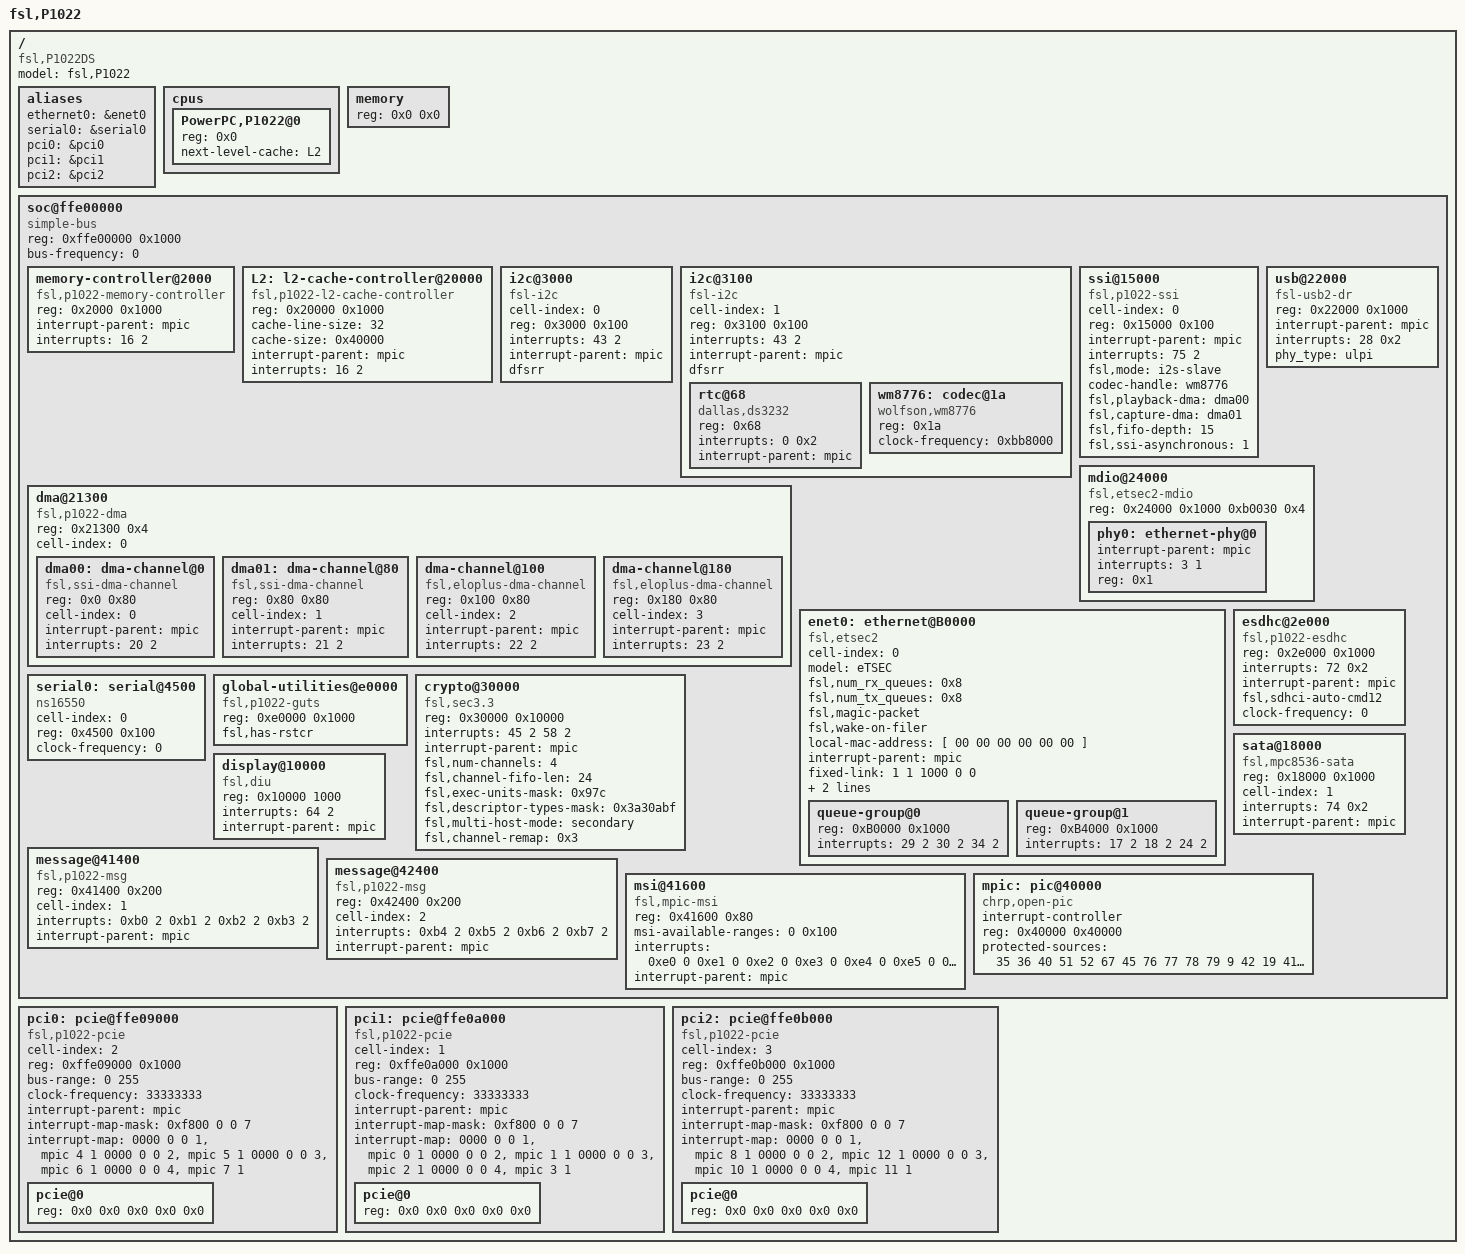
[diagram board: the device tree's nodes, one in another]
/*
 * P1022 DS Core0 Device Tree Source in CAMP mode.
 *
 * In CAMP mode, each core needs to have its own dts. Only mpic and L2 cache
 * can be shared, all the other devices must be assigned to one core only.
 * This dts file allows core0 to have memory, l2, i2c, dma1, global-util, eth0,
 * usb, esdhc, crypto, pcie0, pcie2, sata1.
 *
 * Copyright 2010-2011 Freescale Semiconductor Inc.
 *
 * This program is free software; you can redistribute it and/or modify it
 * under the terms of the GNU General Public License as published by the
 * Free Software Foundation; either version 2 of the License, or (at your
 * option) any later version.
 */

/dts-v1/;
/ {
	model = "fsl,P1022";
	compatible = "fsl,P1022DS", "fsl,P1022DS-CAMP";
	#address-cells = <1>;
	#size-cells = <1>;

	aliases {
		ethernet0 = &enet0;
		serial0 = &serial0;
		pci0 = &pci0;
		pci1 = &pci1;
		pci2 = &pci2;
	};

	cpus {
		#address-cells = <1>;
		#size-cells = <0>;

		PowerPC,P1022@0 {
			device_type = "cpu";
			reg = <0x0>;
			next-level-cache = <&L2>;
		};

	};

	memory {
		device_type = "memory";
		reg = <0x0 0x0>;		// Filled by U-Boot
	};

	soc@ffe00000 {
		#address-cells = <1>;
		#size-cells = <1>;
		device_type = "soc";
		compatible = "simple-bus";
		ranges = <0x0 0xffe00000 0x100000>;
		// CCSRBAR & soc regs, remove once parse code for immrbase fixed
		reg = <0xffe00000 0x1000>;
		bus-frequency = <0>;		// Filled out by uboot.

		memory-controller@2000 {
			compatible = "fsl,p1022-memory-controller";
			reg = <0x2000 0x1000>;
			interrupt-parent = <&mpic>;
			interrupts = <16 2>;
		};

		L2: l2-cache-controller@20000 {
			compatible = "fsl,p1022-l2-cache-controller";
			reg = <0x20000 0x1000>;
			cache-line-size = <32>;	// 32 bytes
			cache-size = <0x40000>;	// L2, 256K
			interrupt-parent = <&mpic>;
			interrupts = <16 2>;
		};

		i2c@3000 {
			#address-cells = <1>;
			#size-cells = <0>;
			cell-index = <0>;
			compatible = "fsl-i2c";
			reg = <0x3000 0x100>;
			interrupts = <43 2>;
			interrupt-parent = <&mpic>;
			dfsrr;
		};

		i2c@3100 {
			#address-cells = <1>;
			#size-cells = <0>;
			cell-index = <1>;
			compatible = "fsl-i2c";
			reg = <0x3100 0x100>;
			interrupts = <43 2>;
			interrupt-parent = <&mpic>;
			dfsrr;
			rtc@68 {
				compatible = "dallas,ds3232";
				reg = <0x68>;
				interrupts = <0 0x2>;
				interrupt-parent = <&mpic>;
			};
			wm8776:codec@1a {
				compatible = "wolfson,wm8776";
				reg = <0x1a>;
				clock-frequency = <0xbb8000>;
			};
		};

		ssi@15000 {
			compatible = "fsl,p1022-ssi";
			cell-index = <0>;
			reg = <0x15000 0x100>;
			interrupt-parent = <&mpic>;
			interrupts = <75 2>;
			fsl,mode = "i2s-slave";
			codec-handle = <&wm8776>;
			fsl,playback-dma = <&dma00>;
			fsl,capture-dma = <&dma01>;
			fsl,fifo-depth = <15>;
			fsl,ssi-asynchronous = <1>;
		};

		dma@21300 {
			#address-cells = <1>;
			#size-cells = <1>;
			compatible = "fsl,p1022-dma", "fsl,eloplus-dma";
			reg = <0x21300 0x4>;
			ranges = <0x0 0x21100 0x200>;
			cell-index = <0>;
			dma00: dma-channel@0 {
				compatible = "fsl,ssi-dma-channel";
				reg = <0x0 0x80>;
				cell-index = <0>;
				interrupt-parent = <&mpic>;
				interrupts = <20 2>;
			};
			dma01: dma-channel@80 {
				compatible = "fsl,ssi-dma-channel";
				reg = <0x80 0x80>;
				cell-index = <1>;
				interrupt-parent = <&mpic>;
				interrupts = <21 2>;
			};
			dma-channel@100 {
				compatible = "fsl,eloplus-dma-channel";
				reg = <0x100 0x80>;
				cell-index = <2>;
				interrupt-parent = <&mpic>;
				interrupts = <22 2>;
			};
			dma-channel@180 {
				compatible = "fsl,eloplus-dma-channel";
				reg = <0x180 0x80>;
				cell-index = <3>;
				interrupt-parent = <&mpic>;
				interrupts = <23 2>;
			};
		};

		usb@22000 {
			#address-cells = <1>;
			#size-cells = <0>;
			compatible = "fsl-usb2-dr";
			reg = <0x22000 0x1000>;
			interrupt-parent = <&mpic>;
			interrupts = <28 0x2>;
			phy_type = "ulpi";
		};

		mdio@24000 {
			#address-cells = <1>;
			#size-cells = <0>;
			compatible = "fsl,etsec2-mdio";
			reg = <0x24000 0x1000 0xb0030 0x4>;

			phy0: ethernet-phy@0 {
				interrupt-parent = <&mpic>;
				interrupts = <3 1>;
				reg = <0x1>;
			};
		};

		enet0: ethernet@B0000 {
			#address-cells = <1>;
			#size-cells = <1>;
			cell-index = <0>;
			device_type = "network";
			model = "eTSEC";
			compatible = "fsl,etsec2";
			fsl,num_rx_queues = <0x8>;
			fsl,num_tx_queues = <0x8>;
			fsl,magic-packet;
			fsl,wake-on-filer;
			local-mac-address = [ 00 00 00 00 00 00 ];
			interrupt-parent = <&mpic>;
			fixed-link = <1 1 1000 0 0>;
			phy-handle = <&phy0>;
			phy-connection-type = "rgmii-id";
			queue-group@0{
				#address-cells = <1>;
				#size-cells = <1>;
				reg = <0xB0000 0x1000>;
				interrupts = <29 2 30 2 34 2>;
			};
			queue-group@1{
				#address-cells = <1>;
				#size-cells = <1>;
				reg = <0xB4000 0x1000>;
				interrupts = <17 2 18 2 24 2>;
			};
		};

		esdhc@2e000 {
			compatible = "fsl,p1022-esdhc", "fsl,esdhc";
			reg = <0x2e000 0x1000>;
			interrupts = <72 0x2>;
			interrupt-parent = <&mpic>;
			fsl,sdhci-auto-cmd12;
			clock-frequency = <0>;
		};

		serial0: serial@4500 {
			cell-index = <0>;
			device_type = "serial";
			compatible = "ns16550";
			reg = <0x4500 0x100>;
			clock-frequency = <0>;
		};

		global-utilities@e0000 {	//global utilities block
			compatible = "fsl,p1022-guts";
			reg = <0xe0000 0x1000>;
			fsl,has-rstcr;
		};

		crypto@30000 {
			compatible = "fsl,sec3.3", "fsl,sec3.1","fsl,sec3.0",
				     "fsl,sec2.4", "fsl,sec2.2","fsl,sec2.1",
				     "fsl,sec2.0";
			reg = <0x30000 0x10000>;
			interrupts = <45 2 58 2>;
			interrupt-parent = <&mpic>;
			fsl,num-channels = <4>;
			fsl,channel-fifo-len = <24>;
			fsl,exec-units-mask = <0x97c>;
			fsl,descriptor-types-mask = <0x3a30abf>;
			fsl,multi-host-mode = "secondary";
			fsl,channel-remap = <0x3>;
		};

		sata@18000 {
			compatible = "fsl,mpc8536-sata", "fsl,pq-sata";
			reg = <0x18000 0x1000>;
			cell-index = <1>;
			interrupts = <74 0x2>;
			interrupt-parent = <&mpic>;
		};

		display@10000 {
			compatible = "fsl,diu", "fsl,p1022-diu";
			reg = <0x10000 1000>;
			interrupts = <64 2>;
			interrupt-parent = <&mpic>;
		};

		message@41400 {
			compatible = "fsl,p1022-msg","fsl,mpic-msg";
			reg = <0x41400 0x200>;
			cell-index = <1>;
			interrupts = <0xb0 2 0xb1 2 0xb2 2 0xb3 2>;
			interrupt-parent = < &mpic >;
		};

		message@42400 {
			compatible = "fsl,p1022-msg","fsl,mpic-msg";
			reg = <0x42400 0x200>;
			cell-index = <2>;
			interrupts = <0xb4 2 0xb5 2 0xb6 2 0xb7 2>;
			interrupt-parent = < &mpic >;
		};

		msi@41600 {
			compatible = "fsl,mpic-msi";
			reg = <0x41600 0x80>;
			msi-available-ranges = <0 0x100>;
			interrupts = <
				0xe0 0
				0xe1 0
				0xe2 0
				0xe3 0
				0xe4 0
				0xe5 0
				0xe6 0
				0xe7 0>;
			interrupt-parent = <&mpic>;
		};

		mpic: pic@40000 {
			interrupt-controller;
			#address-cells = <0>;
			#interrupt-cells = <2>;
			reg = <0x40000 0x40000>;
			compatible = "chrp,open-pic";
			device_type = "open-pic";
			protected-sources = <
			35 36 40 51 52 67 45	/* enet1 SEC-int2*/
			76 77 78 79 9 42	/* dma2 mdio-phy1 serial*/
			19 41 59		/* elbc sata2 spi */
			62 63			/* tdm */
			>;
		};
	};

	pci0: pcie@ffe09000 {
		cell-index = <2>;
		compatible = "fsl,p1022-pcie";
		device_type = "pci";
		#interrupt-cells = <1>;
		#size-cells = <2>;
		#address-cells = <3>;
		reg = <0xffe09000 0x1000>;
		bus-range = <0 255>;
		ranges = <0x2000000 0x0 0xa0000000 0xa0000000 0x0 0x20000000
			  0x1000000 0x0 0x00000000 0xffc10000 0x0 0x10000>;
		clock-frequency = <33333333>;
		interrupt-parent = <&mpic>;
		interrupt-map-mask = <0xf800 0 0 7>;
		interrupt-map = <
			/* IDSEL 0x0 */
			0000 0 0 1 &mpic 4 1
			0000 0 0 2 &mpic 5 1
			0000 0 0 3 &mpic 6 1
			0000 0 0 4 &mpic 7 1
			>;
		pcie@0 {
			reg = <0x0 0x0 0x0 0x0 0x0>;
			#size-cells = <2>;
			#address-cells = <3>;
			device_type = "pci";
			ranges = <0x2000000 0x0 0xa0000000
				  0x2000000 0x0 0xa0000000
				  0x0 0x20000000

				  0x1000000 0x0 0x0
				  0x1000000 0x0 0x0
				  0x0 0x100000>;
		};
	};

	pci1: pcie@ffe0a000 {
		cell-index = <1>;
		compatible = "fsl,p1022-pcie";
		device_type = "pci";
		#interrupt-cells = <1>;
		#size-cells = <2>;
		#address-cells = <3>;
		reg = <0xffe0a000 0x1000>;
		bus-range = <0 255>;
		ranges = <0x2000000 0x0 0xc0000000 0xc0000000 0x0 0x20000000
			  0x1000000 0x0 0x00000000 0xffc20000 0x0 0x10000>;
		clock-frequency = <33333333>;
		interrupt-parent = <&mpic>;
		interrupt-map-mask = <0xf800 0 0 7>;
		interrupt-map = <
			/* IDSEL 0x0 */
			0000 0 0 1 &mpic 0 1
			0000 0 0 2 &mpic 1 1
			0000 0 0 3 &mpic 2 1
			0000 0 0 4 &mpic 3 1
			>;
		pcie@0 {
			reg = <0x0 0x0 0x0 0x0 0x0>;
			#size-cells = <2>;
			#address-cells = <3>;
			device_type = "pci";
			ranges = <0x2000000 0x0 0xc0000000
				  0x2000000 0x0 0xc0000000
				  0x0 0x20000000

				  0x1000000 0x0 0x0
				  0x1000000 0x0 0x0
				  0x0 0x100000>;
		};
	};

	pci2: pcie@ffe0b000 {
		cell-index = <3>;
		compatible = "fsl,p1022-pcie";
		device_type = "pci";
		#interrupt-cells = <1>;
		#size-cells = <2>;
		#address-cells = <3>;
		reg = <0xffe0b000 0x1000>;
		bus-range = <0 255>;
		ranges = <0x2000000 0x0 0x80000000 0x80000000 0x0 0x20000000
			  0x1000000 0x0 0x00000000 0xffc00000 0x0 0x10000>;
		clock-frequency = <33333333>;
		interrupt-parent = <&mpic>;
		interrupt-map-mask = <0xf800 0 0 7>;
		interrupt-map = <
			/* IDSEL 0x0 */
			0000 0 0 1 &mpic 8 1
			0000 0 0 2 &mpic 12 1
			0000 0 0 3 &mpic 10 1
			0000 0 0 4 &mpic 11 1
			>;
		pcie@0 {
			reg = <0x0 0x0 0x0 0x0 0x0>;
			#size-cells = <2>;
			#address-cells = <3>;
			device_type = "pci";
			ranges = <0x2000000 0x0 0x80000000
				  0x2000000 0x0 0x80000000
				  0x0 0x20000000

				  0x1000000 0x0 0x0
				  0x1000000 0x0 0x0
				  0x0 0x100000>;
		};
	};
};
